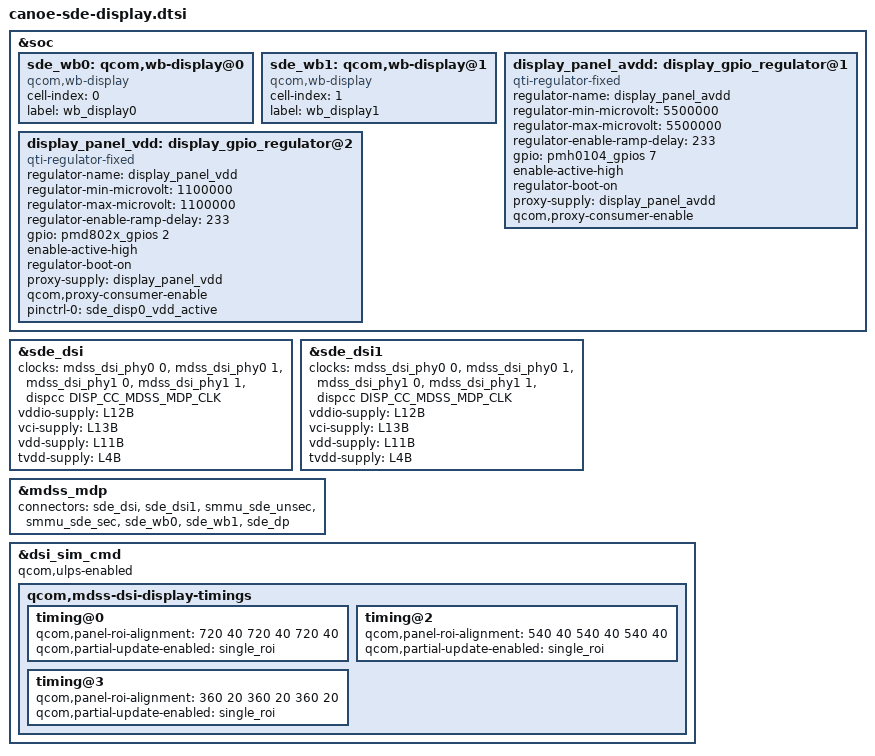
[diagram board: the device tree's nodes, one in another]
// SPDX-License-Identifier: BSD-3-Clause
/*
 * Copyright (c) 2024 Qualcomm Innovation Center, Inc. All rights reserved.
 */

#include "canoe-sde.dtsi"
#include "canoe-sde-display-common.dtsi"
#include <dt-bindings/clock/qcom,dispcc-canoe.h>

&soc {
	sde_wb0: qcom,wb-display@0 {
		compatible = "qcom,wb-display";
		cell-index = <0>;
		label = "wb_display0";
	};

	sde_wb1: qcom,wb-display@1 {
		compatible = "qcom,wb-display";
		cell-index = <1>;
		label = "wb_display1";
	};

	display_panel_avdd: display_gpio_regulator@1 {
		compatible = "qti-regulator-fixed";
		regulator-name = "display_panel_avdd";
		regulator-min-microvolt = <5500000>;
		regulator-max-microvolt = <5500000>;
		regulator-enable-ramp-delay = <233>;
		gpio = <&pmh0104_gpios 7 0>;
		enable-active-high;
		regulator-boot-on;
		proxy-supply = <&display_panel_avdd>;
		qcom,proxy-consumer-enable;
		pinctrl-names = "default";
	};

	display_panel_vdd: display_gpio_regulator@2 {
		compatible = "qti-regulator-fixed";
		regulator-name = "display_panel_vdd";
		regulator-min-microvolt = <1100000>;
		regulator-max-microvolt = <1100000>;
		regulator-enable-ramp-delay = <233>;
		gpio = <&pmd802x_gpios 2 0>;
		enable-active-high;
		regulator-boot-on;
		proxy-supply = <&display_panel_vdd>;
		qcom,proxy-consumer-enable;
		pinctrl-names = "default";
		pinctrl-0 = <&sde_disp0_vdd_active>;
	};
};

&sde_dsi {
	clocks = <&mdss_dsi_phy0 0>,
		<&mdss_dsi_phy0 1>,
		<&mdss_dsi_phy1 0>,
		<&mdss_dsi_phy1 1>,
		/*
		 * Currently the dsi clock handles are under the dsi
		 * controller DT node. As soon as the controller probe
		 * finishes, the dispcc sync state can get called before
		 * the dsi_display probe potentially disturbing the clock
		 * votes for cont_splash use case. Hence we are no longer
		 * protected by the component model in this case against the
		 * disp cc sync state getting triggered after the dsi_ctrl
		 * probe. To protect against this incorrect sync state trigger
		 * add this dummy MDP clk vote handle to the dsi_display
		 * DT node. Since the dsi_display driver does not parse
		 * MDP clock nodes, no actual vote shall be added and this
		 * change is done just to satisfy sync state requirements.
		 */
		<&dispcc DISP_CC_MDSS_MDP_CLK>;
	clock-names = "pll_byte_clk0", "pll_dsi_clk0",
			"pll_byte_clk1", "pll_dsi_clk1",
			"mdp_core_clk";
	vddio-supply = <&L12B>;
	vci-supply = <&L13B>;
	vdd-supply = <&L11B>;
	tvdd-supply = <&L4B>;
};

&sde_dsi1 {
	clocks = <&mdss_dsi_phy0 0>,
		<&mdss_dsi_phy0 1>,
		<&mdss_dsi_phy1 0>,
		<&mdss_dsi_phy1 1>,
		/*
		 * Currently the dsi clock handles are under the dsi
		 * controller DT node. As soon as the controller probe
		 * finishes, the dispcc sync state can get called before
		 * the dsi_display probe potentially disturbing the clock
		 * votes for cont_splash use case. Hence we are no longer
		 * protected by the component model in this case against the
		 * disp cc sync state getting triggered after the dsi_ctrl
		 * probe. To protect against this incorrect sync state trigger
		 * add this dummy MDP clk vote handle to the dsi_display
		 * DT node. Since the dsi_display driver does not parse
		 * MDP clock nodes, no actual vote shall be added and this
		 * change is done just to satisfy sync state requirements.
		 */
		<&dispcc DISP_CC_MDSS_MDP_CLK>;
	clock-names = "pll_byte_clk0", "pll_dsi_clk0",
			"pll_byte_clk1", "pll_dsi_clk1",
			"mdp_core_clk";
	vddio-supply = <&L12B>;
	vci-supply = <&L13B>;
	vdd-supply = <&L11B>;
	tvdd-supply = <&L4B>;
};

&mdss_mdp {
	connectors = <&sde_dsi &sde_dsi1 &smmu_sde_unsec &smmu_sde_sec &sde_wb0 &sde_wb1 &sde_dp>;
};

&dsi_sim_cmd {
	qcom,ulps-enabled;
	qcom,mdss-dsi-display-timings {
		timing@0 { /* WQHD 60FPS cmd vid mode*/
			qcom,panel-roi-alignment = <720 40 720 40 720 40>;
			qcom,partial-update-enabled = "single_roi";
		};

		timing@2 { /* FHD 60FPS cmd mode*/
			qcom,panel-roi-alignment = <540 40 540 40 540 40>;
			qcom,partial-update-enabled = "single_roi";
		};

		timing@3 { /* HD 60FPS cmd mode*/
			qcom,panel-roi-alignment = <360 20 360 20 360 20>;
			qcom,partial-update-enabled = "single_roi";
		};
	};
};
